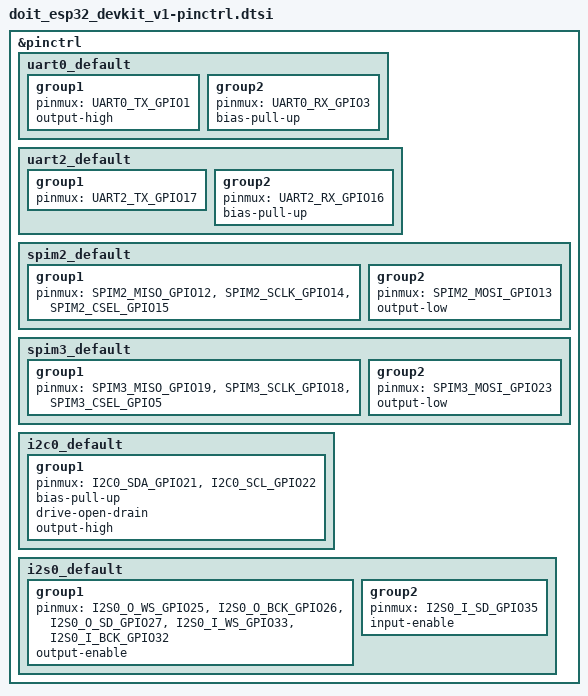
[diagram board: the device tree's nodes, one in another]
/*
 * Copyright (c) 2025 Siratul Islam
 *
 * SPDX-License-Identifier: Apache-2.0
 */

#include <zephyr/dt-bindings/pinctrl/esp-pinctrl-common.h>
#include <dt-bindings/pinctrl/esp32-pinctrl.h>
#include <zephyr/dt-bindings/pinctrl/esp32-gpio-sigmap.h>

&pinctrl {
	uart0_default: uart0_default {
		group1 {
			pinmux = <UART0_TX_GPIO1>;
			output-high;
		};

		group2 {
			pinmux = <UART0_RX_GPIO3>;
			bias-pull-up;
		};
	};

	uart2_default: uart2_default {
		group1 {
			pinmux = <UART2_TX_GPIO17>;
		};

		group2 {
			pinmux = <UART2_RX_GPIO16>;
			bias-pull-up;
		};
	};

	spim2_default: spim2_default {
		group1 {
			pinmux = <SPIM2_MISO_GPIO12>,
				 <SPIM2_SCLK_GPIO14>,
				 <SPIM2_CSEL_GPIO15>;
		};

		group2 {
			pinmux = <SPIM2_MOSI_GPIO13>;
			output-low;
		};
	};

	spim3_default: spim3_default {
		group1 {
			pinmux = <SPIM3_MISO_GPIO19>,
				 <SPIM3_SCLK_GPIO18>,
				 <SPIM3_CSEL_GPIO5>;
		};

		group2 {
			pinmux = <SPIM3_MOSI_GPIO23>;
			output-low;
		};
	};

	i2c0_default: i2c0_default {
		group1 {
			pinmux = <I2C0_SDA_GPIO21>,
				 <I2C0_SCL_GPIO22>;
			bias-pull-up;
			drive-open-drain;
			output-high;
		};
	};

	i2s0_default: i2s0_default {
		group1 {
			pinmux = <I2S0_O_WS_GPIO25>,
				 <I2S0_O_BCK_GPIO26>,
				 <I2S0_O_SD_GPIO27>,
				 <I2S0_I_WS_GPIO33>,
				 <I2S0_I_BCK_GPIO32>;
			output-enable;
		};

		group2 {
			pinmux = <I2S0_I_SD_GPIO35>;
			input-enable;
		};
	};
};
